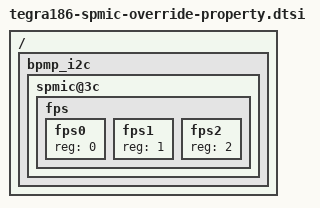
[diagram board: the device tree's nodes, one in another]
/*
 * Copyright (c) 2016, NVIDIA CORPORATION.  All rights reserved.
 *
 * This program is free software; you can redistribute it and/or modify
 * it under the terms of the GNU General Public License as published by
 * the Free Software Foundation; either version 2 of the License, or
 * (at your option) any later version.
 *
 * This program is distributed in the hope that it will be useful, but WITHOUT
 * ANY WARRANTY; without even the implied warranty of MERCHANTABILITY or
 * FITNESS FOR A PARTICULAR PURPOSE.  See the GNU General Public License for
 * more details.
 */

/ {
	bpmp_i2c {
		spmic@3c {
			fps {
				#address-cells = <1>;
				#size-cells = <0>;
				fps0 {
					reg = <0>;
				};

				fps1 {
					reg = <1>;
				};

				fps2 {
					reg = <2>;
				};
			};
		};
	};
};
